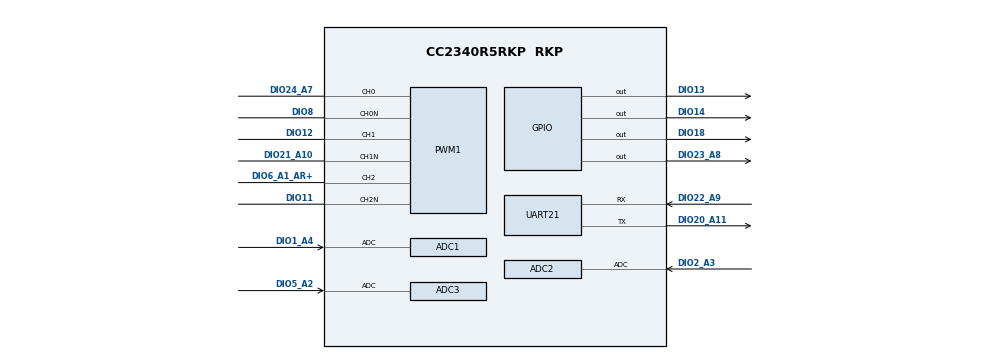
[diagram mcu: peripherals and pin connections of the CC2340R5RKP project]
/**
 * @cliArgs --device "CC2340R5RKP" --part "Default" --package "RKP" --rtos "freertos" --product "simplelink_lowpower_f3_sdk@8.40.00.61"
 * @versions {"tool":"1.22.0+3893"}
 */

/**
 * Import the modules used in this configuration.
 */
const FreeRTOS    = scripting.addModule("/freertos/FreeRTOS");
const ble         = scripting.addModule("/ti/ble5stack/ble");
const CCFG        = scripting.addModule("/ti/devices/CCFG");
const rfdesign    = scripting.addModule("/ti/devices/radioconfig/rfdesign");
const ADC         = scripting.addModule("/ti/drivers/ADC", {}, false);
const ADC1        = ADC.addInstance();
const ADC2        = ADC.addInstance();
const ADC3        = ADC.addInstance();
const ADC4        = ADC.addInstance();
const ADCBuf      = scripting.addModule("/ti/drivers/ADCBuf", {}, false);
const ADCBuf1     = ADCBuf.addInstance();
const AESCCM      = scripting.addModule("/ti/drivers/AESCCM");
const AESCCM1     = AESCCM.addInstance();
const AESCTRDRBG  = scripting.addModule("/ti/drivers/AESCTRDRBG");
const AESCTRDRBG1 = AESCTRDRBG.addInstance();
const AESECB      = scripting.addModule("/ti/drivers/AESECB");
const AESECB1     = AESECB.addInstance();
const Board       = scripting.addModule("/ti/drivers/Board");
const ECDH        = scripting.addModule("/ti/drivers/ECDH");
const ECDH1       = ECDH.addInstance();
const GPIO        = scripting.addModule("/ti/drivers/GPIO");
const GPIO6       = GPIO.addInstance();
const GPIO7       = GPIO.addInstance();
const GPIO8       = GPIO.addInstance();
const GPIO9       = GPIO.addInstance();
const LGPTimer    = scripting.addModule("/ti/drivers/LGPTimer", {}, false);
const LGPTimer1   = LGPTimer.addInstance();
const NVS         = scripting.addModule("/ti/drivers/NVS");
const NVS1        = NVS.addInstance();
const PWM         = scripting.addModule("/ti/drivers/PWM", {}, false);
const PWM1        = PWM.addInstance();
const Power       = scripting.addModule("/ti/drivers/Power");
const RCL         = scripting.addModule("/ti/drivers/RCL");
const RNG         = scripting.addModule("/ti/drivers/RNG");
const RNG1        = RNG.addInstance();
const UART2       = scripting.addModule("/ti/drivers/UART2", {}, false);
const UART21      = UART2.addInstance();
const Button      = scripting.addModule("/ti/drivers/apps/Button", {}, false);
const Button1     = Button.addInstance();
const Button2     = Button.addInstance();
const Settings    = scripting.addModule("/ti/posix/freertos/Settings");

/**
 * Write custom configuration values to the imported modules.
 */
FreeRTOS.heapSize       = 0x00004D50;
FreeRTOS.timerStackSize = 0x00000190;
FreeRTOS.idleStackSize  = 0x00000130;

ble.basicBLE                                                   = true;
ble.disDevBySerUuid                                            = true;
ble.numOfAdvSets                                               = 1;
ble.numOfDefAdvSets                                            = 1;
ble.maxNumPrepareWrites                                        = 10;
ble.hideHealthToolkit                                          = false;
ble.deviceName                                                 = "BLE/BLDC MOTOR";
ble.addressMode                                                = "ADDRMODE_PUBLIC";
ble.defaultTxPowerValue                                        = "8";
ble.radioConfig.codeExportConfig.$name                         = "ti_devices_radioconfig_code_export_param0";
ble.adcNoiseConfig.codeExportConfig.$name                      = "ti_devices_radioconfig_code_export_param1";
ble.connUpdateParamsPeripheral.$name                           = "ti_ble5stack_general_ble_conn_update_params0";
ble.advSet1.$name                                              = "ti_ble5stack_broadcaster_advertisement_set0";
ble.advSet1.advParam1.$name                                    = "ti_ble5stack_broadcaster_advertisement_params0";
ble.advSet1.advData1.$name                                     = "ti_ble5stack_broadcaster_advertisement_data0";
ble.advSet1.advData1.numOfUUIDs16More                          = 1;
ble.advSet1.advData1.UUID016More                               = 0xFFF0;
ble.advSet1.advData1.GAP_ADTYPE_128BIT_MORE                    = true;
ble.advSet1.advData1.numOfUUIDs128More                         = 1;
ble.advSet1.advData1.UUID0128More                              = system.utils.bigInt("B000405104C0C000F0",16);
ble.advSet1.scanRes1.$name                                     = "ti_ble5stack_broadcaster_advertisement_data1";
ble.advSet1.scanRes1.GAP_ADTYPE_PERIPHERAL_CONN_INTERVAL_RANGE = true;

CCFG.ccfgTemplate.$name = "ti_devices_CCFG_CCFGCC23X0Template0";

ADC1.$name                         = "CONFIG_ADC_VSENA";
ADC1.adcChannel.adc.$assign        = "ADC";
ADC1.adcChannel.adc.adcPin.$assign = "DIO1_A4";

ADC2.$name                         = "CONFIG_ADC_VSENB";
ADC2.adcChannel.adc.$assign        = "ADC";
ADC2.adcChannel.adc.adcPin.$assign = "DIO2_A3";

ADC3.$name                         = "CONFIG_ADC_VSENC";
ADC3.adcChannel.adc.$assign        = "ADC";
ADC3.adcChannel.adc.adcPin.$assign = "DIO5_A2";

ADC4.$name = "CONFIG_ADC_VSEN";

ADCBuf1.$name                             = "CONFIG_ADC_ISEN";
ADCBuf1.adcChannels[0].$name              = "CONFIG_ADC_CHANNEL_0";
ADCBuf1.adcChannels[0].adc.adcPin.$assign = "DIO0_A5";

AESCCM1.$name = "CONFIG_AESCCM0";

AESCTRDRBG1.$name = "CONFIG_AESCTRDRBG_0";

AESECB1.$name = "CONFIG_AESECB0";

Board.generateInitializationFunctions = false;

ECDH1.$name = "CONFIG_ECDH0";

GPIO6.$name           = "CONFIG_GPIO_HALLA";
GPIO6.gpioPin.$assign = "DIO23_A8";

GPIO7.$name           = "CONFIG_GPIO_HALLB";
GPIO7.gpioPin.$assign = "DIO18";

GPIO8.$name           = "CONFIG_GPIO_HALLC";
GPIO8.gpioPin.$assign = "DIO13";

GPIO9.$name           = "CONFIG_GPIO_nFAULT_49C";
GPIO9.gpioPin.$assign = "DIO14";

LGPTimer1.$name         = "CONFIG_LGPTIMER_0";
LGPTimer1.timer.$assign = "LGPT0";

NVS1.$name                    = "CONFIG_NVSINTERNAL";
NVS1.internalFlash.$name      = "ti_drivers_nvs_NVSLPF30";
NVS1.internalFlash.regionBase = 0x7C000;
NVS1.internalFlash.regionSize = 0x4000;

PWM1.$name                                          = "CONFIG_PWM_6";
PWM1.timerObject.$name                              = "CONFIG_LGPTIMER_1";
PWM1.timerObject.channel0Connection                 = "Pin";
PWM1.timerObject.channel1Connection                 = "Pin";
PWM1.timerObject.channel2Connection                 = "Pin";
PWM1.timerObject.channel0NConnection                = "Pin";
PWM1.timerObject.channel1NConnection                = "Pin";
PWM1.timerObject.channel2NConnection                = "Pin";
PWM1.timerObject.timer.$assign                      = "LGPT1";
PWM1.timerObject.timer.ch0Pin.$assign               = "DIO24_A7";
PWM1.timerObject.timer.ch1Pin.$assign               = "DIO12";
PWM1.timerObject.timer.ch2Pin.$assign               = "DIO6_A1_AR+";
PWM1.timerObject.timer.ch0NPin.$assign              = "DIO8";
PWM1.timerObject.timer.ch1NPin.$assign              = "DIO21_A10";
PWM1.timerObject.timer.ch2NPin.$assign              = "DIO11";
PWM1.timerObject.ch0PinInstance.$name               = "CONFIG_GPIO_LGPTIMER_1_UH";
PWM1.timerObject.ch1PinInstance.$name               = "CONFIG_GPIO_LGPTIMER_1_VH";
PWM1.timerObject.ch2PinInstance.$name               = "CONFIG_GPIO_LGPTIMER_1_WH";
PWM1.timerObject.ch0NPinInstance.$name              = "CONFIG_GPIO_LGPTIMER_1_UL";
PWM1.timerObject.ch0NPinInstance.initialOutputState = "Low";
PWM1.timerObject.ch1NPinInstance.$name              = "CONFIG_GPIO_LGPTIMER_1_VL";
PWM1.timerObject.ch1NPinInstance.initialOutputState = "Low";
PWM1.timerObject.ch2NPinInstance.$name              = "CONFIG_GPIO_LGPTIMER_1_WL";
PWM1.timerObject.ch2NPinInstance.initialOutputState = "Low";

Power.policyFunction = "Custom";

RNG.rngReturnBehavior = "RNG_RETURN_BEHAVIOR_BLOCKING";
scripting.suppress("This the default noise conditioning key provided by TI, which is acceptable per NIST SP 800-90B\\. However, TI recommends you change this default value to a custom random value for your product", RNG, "noiseConditioningKeyW3");

RNG1.$name = "CONFIG_RNG_0";

UART21.$name                     = "CONFIG_UART2_0";
UART21.txRingBufferSize          = 156;
UART21.rxRingBufferSize          = 156;
UART21.uart.$assign              = "UART0";
UART21.uart.dmaTxChannel.$assign = "DMA_CH1";
UART21.uart.dmaRxChannel.$assign = "DMA_CH0";
UART21.uart.txPin.$assign        = "DIO20_A11";
UART21.uart.rxPin.$assign        = "DIO22_A9";
UART21.rxPinInstance.pull        = "None";

Button1.$name          = "CONFIG_BUTTON_0";
Button1.button.$assign = "DIO10";

Button2.$name          = "CONFIG_BUTTON_1";
Button2.button.$assign = "DIO9";

/**
 * Pinmux solution for unlocked pins/peripherals. This ensures that minor changes to the automatic solver in a future
 * version of the tool will not impact the pinmux you originally saw.  These lines can be completely deleted in order to
 * re-solve from scratch.
 */
ADC4.adcChannel.adc.$suggestSolution        = "ADC";
ADC4.adcChannel.adc.adcPin.$suggestSolution = "DIO7_A0_AR-";
ADCBuf1.adc.$suggestSolution                = "ADC";
ADCBuf1.adc.dataDmaChannel.$suggestSolution = "DMA_CH3";
ADCBuf1.adcChannels[0].adc.$suggestSolution = "ADC";
